VERSION ""

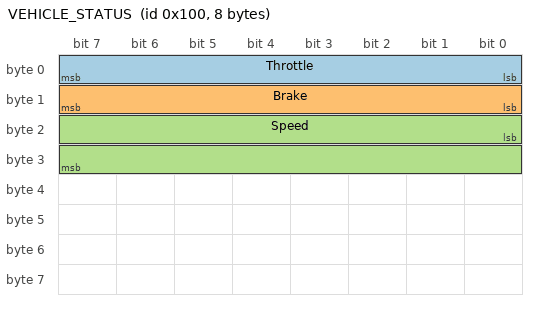
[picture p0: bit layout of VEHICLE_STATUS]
BO_ 256 VEHICLE_STATUS: 8 Vector__XXX
 SG_ Throttle : 0|8@1+ (0.4,0) [0|100] "%" Vector__XXX
 SG_ Brake    : 8|8@1+ (0.4,0) [0|100] "%" Vector__XXX
 SG_ Speed    : 16|16@1+ (0.01,0) [0|250] "km/h" Vector__XXX

BO_ 257 TURN_SIGNALS: 1 Vector__XXX
 SG_ Left  : 0|1@1+ (1,0) [0|1] "" Vector__XXX
 SG_ Right : 1|1@1+ (1,0) [0|1] "" Vector__XXX
